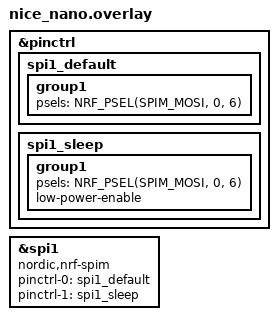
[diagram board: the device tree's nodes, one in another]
&pinctrl {
	spi1_default: spi1_default {
		group1 {
			psels = <NRF_PSEL(SPIM_MOSI, 0, 6)>;
		};
	};

	spi1_sleep: spi1_sleep {
		group1 {
			psels = <NRF_PSEL(SPIM_MOSI, 0, 6)>;
			low-power-enable;
		};
	};
};

&spi1 {
	compatible = "nordic,nrf-spim";
	status = "okay";

	pinctrl-0 = <&spi1_default>;
	pinctrl-1 = <&spi1_sleep>;
	pinctrl-names = "default", "sleep";
};
